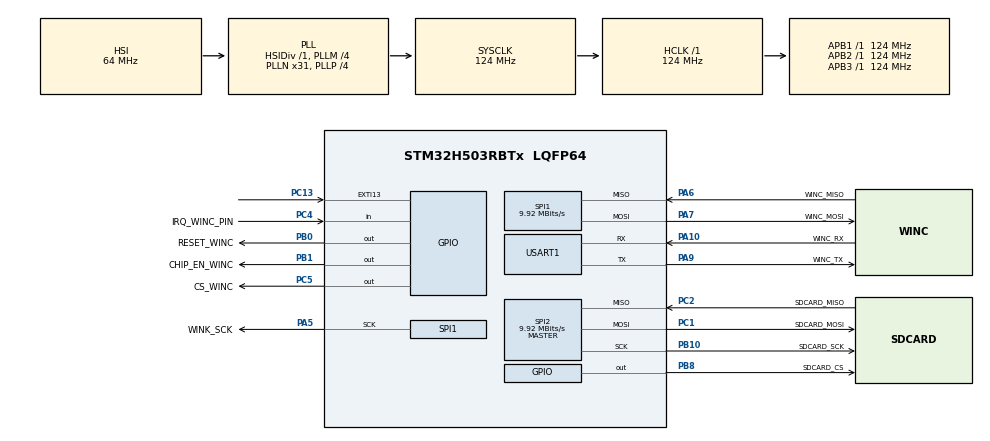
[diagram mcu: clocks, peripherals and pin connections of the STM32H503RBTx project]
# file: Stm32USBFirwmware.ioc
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BOOTPATH.BootPathName=LEGACY
BOOTPATH.UserSelectedBootPath=LEGACY
Mcu.Family=STM32H5
Mcu.Name=STM32H503RBTx
Mcu.Package=LQFP64
NUCLEO-H503RB.BUTTON=1
NUCLEO-H503RB.Bsp_Common_DEMO=true
NUCLEO-H503RB.LD2=false
NUCLEO-H503RB.VCP=true
NVIC.EXTI13_IRQn=true\:0\:0\:false\:false\:true\:false\:true\:true
NVIC.PriorityGroup=NVIC_PRIORITYGROUP_4
NVIC.TIM1_UP_IRQn=true\:15\:0\:false\:false\:true\:false\:true\:true
NVIC.TimeBase=TIM1_UP_IRQn
NVIC.TimeBaseIP=TIM1
PA10.GPIO_Label=WINC_RX
PA10.Mode=Asynchronous
PA10.Signal=USART1_RX
PA3.Signal=USART3_RX
PA4.Signal=USART3_TX
PA5.GPIO_Label=WINK_SCK
PA5.Mode=Full_Duplex_Master
PA5.Signal=SPI1_SCK
PA6.GPIO_Label=WINC_MISO
PA6.GPIO_PuPd=GPIO_PULLUP
PA6.Mode=Full_Duplex_Master
PA6.Signal=SPI1_MISO
PA7.GPIO_Label=WINC_MOSI
PA7.Mode=Full_Duplex_Master
PA7.Signal=SPI1_MOSI
PA9.GPIO_Label=WINC_TX
PA9.Mode=Asynchronous
PA9.Signal=USART1_TX
PB0.GPIO_Label=RESET_WINC
PB0.Signal=GPIO_Output
PB1.GPIO_Label=CHIP_EN_WINC
PB1.PinState=GPIO_PIN_SET
PB1.Signal=GPIO_Output
PB10.GPIO_Label=SDCARD_SCK
PB10.Mode=Full_Duplex_Master
PB10.Signal=SPI2_SCK
PB3(JTDO/TRACESWO).Signal=DEBUG_JTDO-SWO
PB8.GPIO_Label=SDCARD_CS
PB8.Signal=GPIO_Output
PC1.GPIO_Label=SDCARD_MOSI
PC1.GPIO_PuPd=GPIO_PULLUP
PC1.Mode=Full_Duplex_Master
PC1.Signal=SPI2_MOSI
PC13.Signal=GPXTI13
PC2.GPIO_Label=SDCARD_MISO
PC2.Mode=Full_Duplex_Master
PC2.Signal=SPI2_MISO
PC4.GPIO_Label=IRQ_WINC_PIN
PC4.GPIO_PuPd=GPIO_PULLUP
PC4.Signal=GPIO_Input
PC5.GPIO_Label=CS_WINC
PC5.Signal=GPIO_Output
ProjectManager.HeapSize=0x0200
ProjectManager.StackSize=0x0400
ProjectManager.TargetToolchain=STM32CubeIDE
RCC.ADCFreq_Value=124000000
RCC.AHBFreq_Value=124000000
RCC.APB1Freq_Value=124000000
RCC.APB1TimFreq_Value=124000000
RCC.APB2Freq_Value=124000000
RCC.APB2TimFreq_Value=124000000
RCC.APB3Freq_Value=124000000
RCC.CSI_VALUE=4000000
RCC.CortexFreq_Value=124000000
RCC.EPOD_VALUE=64000000
RCC.HCLKFreq_Value=124000000
RCC.HSE_VALUE=24000000
RCC.HSI48_VALUE=48000000
RCC.HSIDiv=RCC_HSI_DIV1
RCC.HSI_VALUE=64000000
RCC.LSE_VALUE=32768
RCC.LSIRC_VALUE=32000
RCC.PLL1P=4
RCC.PLL1Q=25
RCC.PLL2FRACN=0
RCC.PLL2_VCI_Range-AdvancedSettings=RCC_PLL2_VCIRANGE_2
RCC.PLLFRACN=0
RCC.PLLM=4
RCC.PLLN=31
RCC.PLLSourceVirtual=RCC_PLL1_SOURCE_HSI
RCC.SYSCLKFreq_VALUE=124000000
RCC.SYSCLKSource=RCC_SYSCLKSOURCE_PLLCLK
RCC.USBFreq_Value=48000000
RCC.VCOOutputFreq_Value=496000000
SPI1.BaudRatePrescaler=SPI_BAUDRATEPRESCALER_2
SPI1.CalculateBaudRate=9.92 MBits/s
SPI1.DataSize=SPI_DATASIZE_8BIT
SPI1.Direction=SPI_DIRECTION_2LINES
SPI1.Mode=SPI_MODE_MASTER
SPI1.VirtualType=VM_MASTER
SPI2.BaudRatePrescaler=SPI_BAUDRATEPRESCALER_2
SPI2.CalculateBaudRate=9.92 MBits/s
SPI2.DataSize=SPI_DATASIZE_8BIT
SPI2.Direction=SPI_DIRECTION_2LINES
SPI2.Mode=SPI_MODE_MASTER
SPI2.VirtualType=VM_MASTER
USART1.VirtualMode-Asynchronous=VM_ASYNC
VP_BOOTPATH_VS_BOOTPATH.Mode=BP_Activate
VP_CORTEX_M33_NS_VS_Hclk.Mode=Hclk_Mode
VP_ICACHE_VS_ICACHE.Mode=DirectMappedCache
VP_MEMORYMAP_VS_MEMORYMAP.Mode=CurAppReg
VP_NUCLEO-H503RB_VS_BSP_COMMON.Mode=COMMON
VP_PWR_VS_DBSignals.Mode=DisableDeadBatterySignals
VP_PWR_VS_LPOM.Mode=PowerOptimisation
VP_PWR_VS_SECSignals.Mode=Security/Privilege
VP_SYS_VS_tim1.Mode=TIM1
board=NUCLEO-H503RB

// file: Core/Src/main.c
/* USER CODE BEGIN Header */
/**
  ******************************************************************************
  * @file           : main.c
  * @brief          : Main program body
  ******************************************************************************
  * @attention
  *
  * Copyright (c) 2025 STMicroelectronics.
  * All rights reserved.
  *
  * This software is licensed under terms that can be found in the LICENSE file
  * in the root directory of this software component.
  * If no LICENSE file comes with this software, it is provided AS-IS.
  *
  ******************************************************************************
  */
/* USER CODE END Header */
#include "main.h"

/* USER CODE BEGIN Includes */
#include "bootloader_update.h"
#include "conf_winc.h"
/* USER CODE END Includes */

COM_InitTypeDef BspCOMInit;
__IO uint32_t BspButtonState = BUTTON_RELEASED;

SPI_HandleTypeDef hspi1;
SPI_HandleTypeDef hspi2;

UART_HandleTypeDef huart1;

void SystemClock_Config(void);
static void MX_GPIO_Init(void);
static void MX_SPI1_Init(void);
static void MX_SPI2_Init(void);
static void MX_ICACHE_Init(void);
static void MX_USART1_UART_Init(void);

int main(void)
{

  /* MCU Configuration--------------------------------------------------------*/

  /* Reset of all peripherals, Initializes the Flash interface and the Systick. */
  HAL_Init();

  /* Configure the system clock */
  SystemClock_Config();

  /* Initialize all configured peripherals */
  MX_GPIO_Init();
  MX_SPI1_Init();
  MX_SPI2_Init();
  MX_ICACHE_Init();
  MX_USART1_UART_Init();
  /* USER CODE BEGIN 2 */
  winc_enter_rom_loader();

  /* USER CODE END 2 */

  /* Initialize USER push-button, will be used to trigger an interrupt each time it's pressed.*/
  BSP_PB_Init(BUTTON_USER, BUTTON_MODE_EXTI);

  /* Initialize COM1 port (115200, 8 bits (7-bit data + 1 stop bit), no parity */
  BspCOMInit.BaudRate   = 115200;
  BspCOMInit.WordLength = COM_WORDLENGTH_8B;
  BspCOMInit.StopBits   = COM_STOPBITS_1;
  BspCOMInit.Parity     = COM_PARITY_NONE;
  BspCOMInit.HwFlowCtl  = COM_HWCONTROL_NONE;
  if (BSP_COM_Init(COM1, &BspCOMInit) != BSP_ERROR_NONE)
  {
    Error_Handler();
  }

  /* USER CODE BEGIN BSP */

  /* -- Sample board code to switch on led ---- */
  //BSP_LED_On(LED_GREEN);

  /* USER CODE END BSP */

  /* Infinite loop */
  /* USER CODE BEGIN WHILE */
  while (1)
  {

	  while (1) {
	    // PC → WINC
	    if (HAL_UART_Receive(&huart3, &byte,1,0)==HAL_OK)
	      HAL_UART_Transmit(&huart1,&byte,1,0);
	    // WINC → PC
	    if (HAL_UART_Receive(&huart1, &byte,1,0)==HAL_OK)
	      HAL_UART_Transmit(&huart3,&byte,1,0);
	  }
    /* USER CODE END WHILE */

  }
}

void SystemClock_Config(void)
{
  RCC_OscInitTypeDef RCC_OscInitStruct = {0};
  RCC_ClkInitTypeDef RCC_ClkInitStruct = {0};

  /** Configure the main internal regulator output voltage
  */
  __HAL_PWR_VOLTAGESCALING_CONFIG(PWR_REGULATOR_VOLTAGE_SCALE2);

  while(!__HAL_PWR_GET_FLAG(PWR_FLAG_VOSRDY)) {}

  /** Initializes the RCC Oscillators according to the specified parameters
  * in the RCC_OscInitTypeDef structure.
  */
  RCC_OscInitStruct.OscillatorType = RCC_OSCILLATORTYPE_HSI;
  RCC_OscInitStruct.HSIState = RCC_HSI_ON;
  RCC_OscInitStruct.HSIDiv = RCC_HSI_DIV1;
  RCC_OscInitStruct.HSICalibrationValue = RCC_HSICALIBRATION_DEFAULT;
  RCC_OscInitStruct.PLL.PLLState = RCC_PLL_ON;
  RCC_OscInitStruct.PLL.PLLSource = RCC_PLL1_SOURCE_HSI;
  RCC_OscInitStruct.PLL.PLLM = 4;
  RCC_OscInitStruct.PLL.PLLN = 31;
  RCC_OscInitStruct.PLL.PLLP = 4;
  RCC_OscInitStruct.PLL.PLLQ = 25;
  RCC_OscInitStruct.PLL.PLLR = 2;
  RCC_OscInitStruct.PLL.PLLRGE = RCC_PLL1_VCIRANGE_3;
  RCC_OscInitStruct.PLL.PLLVCOSEL = RCC_PLL1_VCORANGE_WIDE;
  RCC_OscInitStruct.PLL.PLLFRACN = 0;
  if (HAL_RCC_OscConfig(&RCC_OscInitStruct) != HAL_OK)
  {
    Error_Handler();
  }

  /** Initializes the CPU, AHB and APB buses clocks
  */
  RCC_ClkInitStruct.ClockType = RCC_CLOCKTYPE_HCLK|RCC_CLOCKTYPE_SYSCLK
                              |RCC_CLOCKTYPE_PCLK1|RCC_CLOCKTYPE_PCLK2
                              |RCC_CLOCKTYPE_PCLK3;
  RCC_ClkInitStruct.SYSCLKSource = RCC_SYSCLKSOURCE_PLLCLK;
  RCC_ClkInitStruct.AHBCLKDivider = RCC_SYSCLK_DIV1;
  RCC_ClkInitStruct.APB1CLKDivider = RCC_HCLK_DIV1;
  RCC_ClkInitStruct.APB2CLKDivider = RCC_HCLK_DIV1;
  RCC_ClkInitStruct.APB3CLKDivider = RCC_HCLK_DIV1;

  if (HAL_RCC_ClockConfig(&RCC_ClkInitStruct, FLASH_LATENCY_4) != HAL_OK)
  {
    Error_Handler();
  }

  /** Configure the programming delay
  */
  __HAL_FLASH_SET_PROGRAM_DELAY(FLASH_PROGRAMMING_DELAY_2);
}

static void MX_ICACHE_Init(void)
{

  /** Enable instruction cache in 1-way (direct mapped cache)
  */
  if (HAL_ICACHE_ConfigAssociativityMode(ICACHE_1WAY) != HAL_OK)
  {
    Error_Handler();
  }
  if (HAL_ICACHE_Enable() != HAL_OK)
  {
    Error_Handler();
  }

}

static void MX_SPI1_Init(void)
{

  /* SPI1 parameter configuration*/
  hspi1.Instance = SPI1;
  hspi1.Init.Mode = SPI_MODE_MASTER;
  hspi1.Init.Direction = SPI_DIRECTION_2LINES;
  hspi1.Init.DataSize = SPI_DATASIZE_8BIT;
  hspi1.Init.CLKPolarity = SPI_POLARITY_LOW;
  hspi1.Init.CLKPhase = SPI_PHASE_1EDGE;
  hspi1.Init.NSS = SPI_NSS_SOFT;
  hspi1.Init.BaudRatePrescaler = SPI_BAUDRATEPRESCALER_2;
  hspi1.Init.FirstBit = SPI_FIRSTBIT_MSB;
  hspi1.Init.TIMode = SPI_TIMODE_DISABLE;
  hspi1.Init.CRCCalculation = SPI_CRCCALCULATION_DISABLE;
  hspi1.Init.CRCPolynomial = 0x7;
  hspi1.Init.NSSPMode = SPI_NSS_PULSE_ENABLE;
  hspi1.Init.NSSPolarity = SPI_NSS_POLARITY_LOW;
  hspi1.Init.FifoThreshold = SPI_FIFO_THRESHOLD_01DATA;
  hspi1.Init.MasterSSIdleness = SPI_MASTER_SS_IDLENESS_00CYCLE;
  hspi1.Init.MasterInterDataIdleness = SPI_MASTER_INTERDATA_IDLENESS_00CYCLE;
  hspi1.Init.MasterReceiverAutoSusp = SPI_MASTER_RX_AUTOSUSP_DISABLE;
  hspi1.Init.MasterKeepIOState = SPI_MASTER_KEEP_IO_STATE_DISABLE;
  hspi1.Init.IOSwap = SPI_IO_SWAP_DISABLE;
  hspi1.Init.ReadyMasterManagement = SPI_RDY_MASTER_MANAGEMENT_INTERNALLY;
  hspi1.Init.ReadyPolarity = SPI_RDY_POLARITY_HIGH;
  if (HAL_SPI_Init(&hspi1) != HAL_OK)
  {
    Error_Handler();
  }

}

static void MX_SPI2_Init(void)
{

  /* SPI2 parameter configuration*/
  hspi2.Instance = SPI2;
  hspi2.Init.Mode = SPI_MODE_MASTER;
  hspi2.Init.Direction = SPI_DIRECTION_2LINES;
  hspi2.Init.DataSize = SPI_DATASIZE_8BIT;
  hspi2.Init.CLKPolarity = SPI_POLARITY_LOW;
  hspi2.Init.CLKPhase = SPI_PHASE_1EDGE;
  hspi2.Init.NSS = SPI_NSS_SOFT;
  hspi2.Init.BaudRatePrescaler = SPI_BAUDRATEPRESCALER_2;
  hspi2.Init.FirstBit = SPI_FIRSTBIT_MSB;
  hspi2.Init.TIMode = SPI_TIMODE_DISABLE;
  hspi2.Init.CRCCalculation = SPI_CRCCALCULATION_DISABLE;
  hspi2.Init.CRCPolynomial = 0x7;
  hspi2.Init.NSSPMode = SPI_NSS_PULSE_ENABLE;
  hspi2.Init.NSSPolarity = SPI_NSS_POLARITY_LOW;
  hspi2.Init.FifoThreshold = SPI_FIFO_THRESHOLD_01DATA;
  hspi2.Init.MasterSSIdleness = SPI_MASTER_SS_IDLENESS_00CYCLE;
  hspi2.Init.MasterInterDataIdleness = SPI_MASTER_INTERDATA_IDLENESS_00CYCLE;
  hspi2.Init.MasterReceiverAutoSusp = SPI_MASTER_RX_AUTOSUSP_DISABLE;
  hspi2.Init.MasterKeepIOState = SPI_MASTER_KEEP_IO_STATE_DISABLE;
  hspi2.Init.IOSwap = SPI_IO_SWAP_DISABLE;
  hspi2.Init.ReadyMasterManagement = SPI_RDY_MASTER_MANAGEMENT_INTERNALLY;
  hspi2.Init.ReadyPolarity = SPI_RDY_POLARITY_HIGH;
  if (HAL_SPI_Init(&hspi2) != HAL_OK)
  {
    Error_Handler();
  }

}

static void MX_USART1_UART_Init(void)
{

  huart1.Instance = USART1;
  huart1.Init.BaudRate = 115200;
  huart1.Init.WordLength = UART_WORDLENGTH_8B;
  huart1.Init.StopBits = UART_STOPBITS_1;
  huart1.Init.Parity = UART_PARITY_NONE;
  huart1.Init.Mode = UART_MODE_TX_RX;
  huart1.Init.HwFlowCtl = UART_HWCONTROL_NONE;
  huart1.Init.OverSampling = UART_OVERSAMPLING_16;
  huart1.Init.OneBitSampling = UART_ONE_BIT_SAMPLE_DISABLE;
  huart1.Init.ClockPrescaler = UART_PRESCALER_DIV1;
  huart1.AdvancedInit.AdvFeatureInit = UART_ADVFEATURE_NO_INIT;
  if (HAL_UART_Init(&huart1) != HAL_OK)
  {
    Error_Handler();
  }
  if (HAL_UARTEx_SetTxFifoThreshold(&huart1, UART_TXFIFO_THRESHOLD_1_8) != HAL_OK)
  {
    Error_Handler();
  }
  if (HAL_UARTEx_SetRxFifoThreshold(&huart1, UART_RXFIFO_THRESHOLD_1_8) != HAL_OK)
  {
    Error_Handler();
  }
  if (HAL_UARTEx_DisableFifoMode(&huart1) != HAL_OK)
  {
    Error_Handler();
  }

}

static void MX_GPIO_Init(void)
{
  GPIO_InitTypeDef GPIO_InitStruct = {0};

  /* GPIO Ports Clock Enable */
  __HAL_RCC_GPIOC_CLK_ENABLE();
  __HAL_RCC_GPIOA_CLK_ENABLE();
  __HAL_RCC_GPIOB_CLK_ENABLE();

  /*Configure GPIO pin Output Level */
  HAL_GPIO_WritePin(CS_WINC_GPIO_Port, CS_WINC_Pin, GPIO_PIN_RESET);

  /*Configure GPIO pin Output Level */
  HAL_GPIO_WritePin(GPIOB, RESET_WINC_Pin|SDCARD_CS_Pin, GPIO_PIN_RESET);

  /*Configure GPIO pin Output Level */
  HAL_GPIO_WritePin(CHIP_EN_WINC_GPIO_Port, CHIP_EN_WINC_Pin, GPIO_PIN_SET);

  /*Configure GPIO pin : PC13 */
  GPIO_InitStruct.Pin = GPIO_PIN_13;
  GPIO_InitStruct.Mode = GPIO_MODE_IT_RISING;
  GPIO_InitStruct.Pull = GPIO_NOPULL;
  HAL_GPIO_Init(GPIOC, &GPIO_InitStruct);

  /*Configure GPIO pin : IRQ_WINC_PIN_Pin */
  GPIO_InitStruct.Pin = IRQ_WINC_PIN_Pin;
  GPIO_InitStruct.Mode = GPIO_MODE_INPUT;
  GPIO_InitStruct.Pull = GPIO_PULLUP;
  HAL_GPIO_Init(IRQ_WINC_PIN_GPIO_Port, &GPIO_InitStruct);

  /*Configure GPIO pin : CS_WINC_Pin */
  GPIO_InitStruct.Pin = CS_WINC_Pin;
  GPIO_InitStruct.Mode = GPIO_MODE_OUTPUT_PP;
  GPIO_InitStruct.Pull = GPIO_NOPULL;
  GPIO_InitStruct.Speed = GPIO_SPEED_FREQ_LOW;
  HAL_GPIO_Init(CS_WINC_GPIO_Port, &GPIO_InitStruct);

  /*Configure GPIO pins : RESET_WINC_Pin CHIP_EN_WINC_Pin SDCARD_CS_Pin */
  GPIO_InitStruct.Pin = RESET_WINC_Pin|CHIP_EN_WINC_Pin|SDCARD_CS_Pin;
  GPIO_InitStruct.Mode = GPIO_MODE_OUTPUT_PP;
  GPIO_InitStruct.Pull = GPIO_NOPULL;
  GPIO_InitStruct.Speed = GPIO_SPEED_FREQ_LOW;
  HAL_GPIO_Init(GPIOB, &GPIO_InitStruct);

}

void HAL_TIM_PeriodElapsedCallback(TIM_HandleTypeDef *htim)
{
  if (htim->Instance == TIM1)
  {
    HAL_IncTick();
  }
}

/**
  * @brief BSP Push Button callback
  * @param Button Specifies the pressed button
  * @retval None
  */
void BSP_PB_Callback(Button_TypeDef Button)
{
  if (Button == BUTTON_USER)
  {
    BspButtonState = BUTTON_PRESSED;
  }
}

void Error_Handler(void)
{
  __disable_irq();
  while (1)
  {
  }
}
